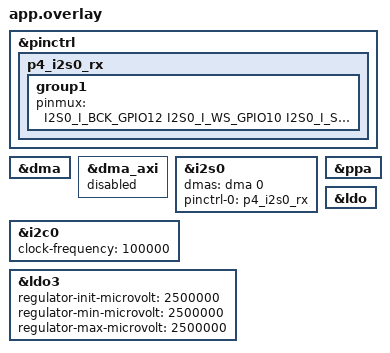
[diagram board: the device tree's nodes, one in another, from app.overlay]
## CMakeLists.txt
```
# SPDX-License-Identifier: MPL-2.0
cmake_minimum_required(VERSION 3.28)
find_package(Zephyr REQUIRED HINTS $ENV{ZEPHYR_BASE})
project(p4_microblocks LANGUAGES C CXX)
get_filename_component(repo "${CMAKE_CURRENT_SOURCE_DIR}/../../.." ABSOLUTE)
execute_process(COMMAND ${Python3_EXECUTABLE} "${repo}/tools/apply_p4_zephyr_patches.py"
  --zephyr "${ZEPHYR_BASE}" --require-applied COMMAND_ERROR_IS_FATAL ANY)
if(NOT SMALLVM_SOURCE_DIR)
  set(SMALLVM_SOURCE_DIR "${repo}/build-artifacts/p4-sources/smallvm")
endif()
set(vm_root "${CMAKE_CURRENT_BINARY_DIR}/smallvm")
execute_process(COMMAND ${Python3_EXECUTABLE} "${repo}/tools/prepare_p4_zephyr_runtime.py"
  "${SMALLVM_SOURCE_DIR}" "${vm_root}" COMMAND_ERROR_IS_FATAL ANY)
target_include_directories(app PRIVATE "${vm_root}" "${vm_root}/vm" "${repo}/common/image" "${repo}/common/audio" "${repo}/common/media" src "${ZEPHYR_BASE}/drivers/video")
target_include_directories(app PRIVATE "${repo}/common/nn" "${repo}/common/i2c")
target_compile_definitions(app PRIVATE SMALLVM_ZEPHYR=1 HAS_BOARD_HOOKS=1 IMAGE_ALLOC_EXTERNAL=1 AUDIO_ALLOC_EXTERNAL=1 MEDIA_ALLOC_EXTERNAL=1)
if(CONFIG_ESP_HOSTED_MCU)
  target_include_directories(app PRIVATE "${ZEPHYR_BASE}/drivers/misc/esp_hosted_mcu")
endif()
target_sources(app PRIVATE src/main.c src/platform.c src/image_primitives.c src/camera_backend.c
  src/p4_sensors.c src/p4_csi.c src/audio_backend.c src/whistle_backend.c src/media_protocol.c src/c6_trace.c
  "${repo}/common/image/image_store.c"
  "${repo}/common/audio/audio_store.c"
  "${repo}/common/media/result_store.c"
  ${vm_root}/vm/interp.c ${vm_root}/vm/runtime.c ${vm_root}/vm/mem.c
  ${vm_root}/vm/persist.c ${vm_root}/vm/dataPrims.c ${vm_root}/vm/varPrims.c
  ${vm_root}/vm/tinyJSON.c ${vm_root}/vm/mbFont.c ${vm_root}/vm/boardHooks.c)
target_sources(app PRIVATE src/neural_primitives.c "${repo}/common/nn/nn_contract.c")
target_sources(app PRIVATE src/discovery_backend.c src/discovery_primitives.c "${repo}/common/i2c/discovery.c")
target_sources(app PRIVATE src/ppa_backend.c)

# Actual RoboEyes with a native framebuffer facade; no ArduinoCore dependency.
if(NOT ROBOEYES_SOURCE_DIR)
  set(ROBOEYES_SOURCE_DIR "${repo}/build-artifacts/roboeyes")
endif()
execute_process(COMMAND ${Python3_EXECUTABLE} "${repo}/tools/fetch_roboeyes.py"
  --output "${ROBOEYES_SOURCE_DIR}" --verify COMMAND_ERROR_IS_FATAL ANY)
target_include_directories(app PRIVATE "${repo}/common/eyes" "${repo}/common/pose" "${ROBOEYES_SOURCE_DIR}/src")
target_sources(app PRIVATE src/eyes_backend.c src/eyes_primitives.c
  "${repo}/common/eyes/oled.c" "${repo}/common/eyes/roboeyes.cpp" "${repo}/common/pose/pose.c"
  src/pose_camera.c src/camera_tuning.c src/serial_speed.c "${repo}/common/pose/camera_wire.c" "${repo}/common/pose/face.c" "${repo}/common/pose/serial_rate.c")

# Portable JSON service; append its primitive set without changing p4:* indices.
target_include_directories(app PRIVATE "${repo}/common/json" "${repo}/third_party/yyjson")
target_sources(app PRIVATE "${repo}/common/json/json_service.c" "${repo}/common/json/json_primitives.c" "${repo}/third_party/yyjson/yyjson.c")
set_source_files_properties("${repo}/third_party/yyjson/yyjson.c" PROPERTIES COMPILE_OPTIONS "-include;${repo}/common/json/json_config.h")

target_include_directories(app PRIVATE "${repo}/common/automation")
target_sources(app PRIVATE "${repo}/common/automation/clock.c" "${repo}/common/automation/steps.c" "${repo}/common/automation/primitives.c")
target_include_directories(app PRIVATE "${repo}/common/storage")
target_sources(app PRIVATE "${repo}/common/storage/storage.c" "${repo}/common/storage/storage_primitives.c"
  "${repo}/common/storage/dispatcher.c" "${repo}/common/storage/wire.c"
  "${repo}/common/storage/controller.c" "${repo}/common/storage/storage_protocol.c")
target_sources(app PRIVATE src/kws_primitives.c src/voice_primitives.c)
if(P4_VOICE_MODEL)
  if(NOT P4_KWS_MODEL)
    message(FATAL_ERROR "Voice commands share the KWS worker; also supply the pinned P4_KWS_MODEL")
  endif()
  set(voice_generated "${CMAKE_CURRENT_BINARY_DIR}/voice")
  get_filename_component(voice_model_dir "${P4_VOICE_MODEL}" DIRECTORY)
  get_filename_component(voice_model_stem "${P4_VOICE_MODEL}" NAME_WE)
  set_property(DIRECTORY APPEND PROPERTY CMAKE_CONFIGURE_DEPENDS "${repo}/bilingual-kws/scripts/prepare_firmware.py" "${P4_VOICE_MODEL}" "${voice_model_dir}/${voice_model_stem}.json")
  execute_process(COMMAND ${Python3_EXECUTABLE} "${repo}/bilingual-kws/scripts/prepare_firmware.py"
    --model "${P4_VOICE_MODEL}" --output "${voice_generated}" COMMAND_ERROR_IS_FATAL ANY)
  target_compile_definitions(app PRIVATE P4_VOICE_COMMANDS=1)
  target_include_directories(app PRIVATE "${voice_generated}" "${repo}/bilingual-kws/esp32p4/integration")
  target_sources(app PRIVATE "${voice_generated}/voice_assets.S" "${repo}/bilingual-kws/esp32p4/integration/decision.c")
endif()
if(P4_KWS_MODEL)
  if(NOT CONFIG_P4_NEURAL OR NOT P4_TFLM_SOURCE)
    message(FATAL_ERROR "KWS requires the pinned TFLM neural profile")
  endif()
  set(kws_generated "${CMAKE_CURRENT_BINARY_DIR}/kws")
  set(kws_args --tflm "${P4_TFLM_SOURCE}" --model "${P4_KWS_MODEL}" --output "${kws_generated}")
  if(P4_KWS_POSITIVE AND P4_KWS_NEGATIVE)
    list(APPEND kws_args --positive "${P4_KWS_POSITIVE}" --negative "${P4_KWS_NEGATIVE}")
  endif()
  set_property(DIRECTORY APPEND PROPERTY CMAKE_CONFIGURE_DEPENDS "${repo}/tools/prepare_p4_kws.py" "${repo}/tools/prepare_p4_kws_frontend.py" "${P4_KWS_MODEL}")
  execute_process(COMMAND ${Python3_EXECUTABLE} "${repo}/tools/prepare_p4_kws.py" ${kws_args} COMMAND_ERROR_IS_FATAL ANY)
  set(kws_frontend "${P4_TFLM_SOURCE}/tensorflow/lite/experimental/microfrontend/lib")
  set(kws_external "${kws_generated}/filterbank_util_checked.c")
  foreach(source filterbank frontend frontend_util log_lut log_scale log_scale_util noise_reduction noise_reduction_util pcan_gain_control pcan_gain_control_util window window_util)
    list(APPEND kws_external "${kws_frontend}/${source}.c")
  endforeach()
  foreach(source fft fft_util kiss_fft_int16)
    list(APPEND kws_external "${kws_frontend}/${source}.cc")
  endforeach()
  # Redirect only frontend allocations; never alter the TFLM/custom NN allocator.
  set_source_files_properties(${kws_external} PROPERTIES COMPILE_OPTIONS "-include;${repo}/common/kws/alloc_redirect.h")
  target_include_directories(app PRIVATE "${repo}/common/kws" "${kws_generated}" "${P4_TFLM_SOURCE}/third_party_static/kissfft")
  target_sources(app PRIVATE src/kws_backend.cpp "${repo}/common/kws/features.c" "${kws_generated}/kws_assets.S" ${kws_external})
else()
  target_sources(app PRIVATE src/kws_stub.c)
endif()
if(CONFIG_P4_NEURAL)
  if(NOT P4_TFLM_SOURCE)
    message(FATAL_ERROR "Pass P4_TFLM_SOURCE for the pinned TFLM module and ZEPHYR_EXTRA_MODULES")
  endif()
  set(nn_generated "${CMAKE_CURRENT_BINARY_DIR}/neural")
  set_property(DIRECTORY APPEND PROPERTY CMAKE_CONFIGURE_DEPENDS "${repo}/tools/prepare_p4_neural.py")
  execute_process(COMMAND ${Python3_EXECUTABLE} "${repo}/tools/prepare_p4_neural.py"
    --source "${ZEPHYR_BASE}/samples/modules/tflite-micro/hello_world/src/model.cpp"
    --tflm "${P4_TFLM_SOURCE}" --output "${nn_generated}" COMMAND_ERROR_IS_FATAL ANY)
  # Error strings must never corrupt the binary SmallVM transport on UART0.
  zephyr_compile_definitions(TF_LITE_STRIP_ERROR_STRINGS)
  target_include_directories(app PRIVATE "${nn_generated}")
  target_sources(app PRIVATE src/neural_backend.cpp "${nn_generated}/neural_builtin.S")
else()
  target_sources(app PRIVATE src/neural_stub.c)
endif()
# Native HAL only: no esp_driver_cam/ISP FreeRTOS drivers are linked.
if(CONFIG_P4_HOSTED)
  if(NOT TARGET modules__nanopb OR NOT CONFIG_ESP_SPIRAM)
    message(FATAL_ERROR "Hosted RPC isolation requires pinned nanopb and initialized PSRAM")
  endif()
  target_compile_options(modules__nanopb PRIVATE "SHELL:-include ${CMAKE_CURRENT_SOURCE_DIR}/src/rpc_allocator.h")
  target_sources(app PRIVATE src/rpc_allocator.c src/rpc_decode.c)
  add_custom_target(p4_rpc_memory_validate ALL DEPENDS zephyr_final
    COMMAND ${Python3_EXECUTABLE} "${repo}/tools/check_p4_rpc_memory.py"
      --elf "${CMAKE_BINARY_DIR}/zephyr/zephyr.elf" --objdump "${CMAKE_OBJDUMP}")
  if(NOT CONFIG_COMMON_LIBC_MALLOC OR NOT CONFIG_COMMON_LIBC_MALLOC_ARENA_SIZE EQUAL -1)
    message(FATAL_ERROR "Hosted memory guard requires the audited automatic libc arena")
  endif()
  if(CONFIG_HTTP_SERVER_VERSION_2 OR CONFIG_NET_SOCKETS_OFFLOAD)
    message(FATAL_ERROR "Re-audit asset buffer ownership before enabling HTTP/2 or socket offload")
  endif()
  zephyr_linker_section(NAME http_resource_desc_p4_http KVMA RAM_REGION GROUP RODATA_REGION)
  zephyr_linker_sources(SECTIONS sections-rom.ld)
  if(NOT P4_HOSTED_ASSETS_DIR)
    set(P4_HOSTED_ASSETS_DIR "${repo}/build-artifacts/p4-hosted-assets")
  endif()
  if(NOT EXISTS "${P4_HOSTED_ASSETS_DIR}/assets.c")
    message(FATAL_ERROR "Run tools/package_p4_hosted.py before building hosted profile")
  endif()
  target_sources(app PRIVATE src/hosted_transport.c src/hosted_server.c src/network_backend.c "${P4_HOSTED_ASSETS_DIR}/assets.c")
  set(hosted_layout_args --elf "${CMAKE_BINARY_DIR}/zephyr/zephyr.elf" --image "${CMAKE_BINARY_DIR}/zephyr/zephyr.bin" --assets "${P4_HOSTED_ASSETS_DIR}/assets.bin" --dts "${CMAKE_BINARY_DIR}/zephyr/zephyr.dts")
  if(NOT P4_WHISTLE_MODEL)
    list(APPEND hosted_layout_args --allow-no-model)
  endif()
  add_custom_target(p4_hosted_layout ALL DEPENDS zephyr_final
    COMMAND ${Python3_EXECUTABLE} "${repo}/tools/check_p4_hosted_layout.py" ${hosted_layout_args})
endif()
target_sources(app PRIVATE
  ${ZEPHYR_HAL_ESPRESSIF_MODULE_DIR}/components/esp_hal_cam/mipi_csi_hal.c
  ${ZEPHYR_HAL_ESPRESSIF_MODULE_DIR}/components/esp_hal_cam/esp32p4/mipi_csi_periph.c
  ${ZEPHYR_HAL_ESPRESSIF_MODULE_DIR}/components/esp_hal_dma/dw_gdma_hal.c)

if(P4_WHISTLE_MODEL)
  if(NOT P4_WHISTLE_SOURCES)
    set(P4_WHISTLE_SOURCES "${repo}/build-artifacts/whistle-sources")
  endif()
  set(whistle_generated "${CMAKE_CURRENT_BINARY_DIR}/whistle")
  set(whistle_args --sources "${P4_WHISTLE_SOURCES}" --model "${P4_WHISTLE_MODEL}" --output "${whistle_generated}")
  if(P4_WHISTLE_FIXTURE)
    list(APPEND whistle_args --fixture "${P4_WHISTLE_FIXTURE}")
    target_compile_definitions(app PRIVATE P4_WHISTLE_FIXTURE=1)
  endif()
  execute_process(COMMAND ${Python3_EXECUTABLE} "${repo}/tools/prepare_p4_whistle.py" ${whistle_args}
    COMMAND_ERROR_IS_FATAL ANY)
  target_compile_definitions(app PRIVATE P4_WHISTLE=1)
  target_include_directories(app PRIVATE "${P4_WHISTLE_SOURCES}/engine/include")
  target_sources(app PRIVATE "${whistle_generated}/whistle_assets.S")
  foreach(source nd_cact nd_quant nd_tokenizer nd_ledcmd nd_whistle)
    target_sources(app PRIVATE "${whistle_generated}/${source}_zephyr.c")
  endforeach()
  add_custom_target(p4_whistle_validate ALL DEPENDS zephyr_final
    COMMAND ${Python3_EXECUTABLE} "${repo}/tools/check_p4_whistle_image.py"
      --elf "${CMAKE_BINARY_DIR}/zephyr/zephyr.elf"
      --bin "${CMAKE_BINARY_DIR}/zephyr/zephyr.bin")
endif()
```

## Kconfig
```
# SPDX-License-Identifier: MPL-2.0
mainmenu "Native P4 MicroBlocks"
source "Kconfig.zephyr"
config P4_HOSTED
 bool "P4-hosted editor on the approved station network"
 depends on WIFI_ESP_HOSTED_MCU_DEFER_STATION
 default n
config P4_NEURAL
 bool "Bounded native TFLM dense model backend"
 depends on TENSORFLOW_LITE_MICRO && CPP
 default n
config P4_IMX219_EXPOSURE_LINES
 int "IMX219 manual exposure in lines (no AE)"
 range 4 1156
 default 800
config P4_IMX219_ANALOG_GAIN
 int "IMX219 analogue gain register (0=1x, 232=10.67x)"
 range 0 232
 default 128
config P4_IMX219_DIGITAL_GAIN
 int "IMX219 digital gain register (256=1x)"
 range 256 4095
 default 256
config P4_IMX219_TEST_PATTERN
 int "IMX219 diagnostic test pattern; 0 is real imaging, 2 is colour bars"
 range 0 4
 default 0
```

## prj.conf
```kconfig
CONFIG_CONSOLE=n
CONFIG_UART_CONSOLE=n
CONFIG_SERIAL=y
CONFIG_UART_INTERRUPT_DRIVEN=y
CONFIG_UART_USE_RUNTIME_CONFIGURE=y
CONFIG_LOG=n
CONFIG_MAIN_STACK_SIZE=16384
CONFIG_HEAP_MEM_POOL_SIZE=16384
CONFIG_PICOLIBC=y
CONFIG_PICOLIBC_IO_FLOAT=y
CONFIG_CBPRINTF_FP_SUPPORT=y
CONFIG_ESP_SPIRAM=y
CONFIG_ESP_SPIRAM_HEAP_SIZE=16777216
CONFIG_ESP_SPIRAM_MEMTEST=y
CONFIG_I2C=y
CONFIG_CPP=y
CONFIG_STD_CPP17=y
CONFIG_RING_BUFFER=y
CONFIG_GPIO=y
CONFIG_ASSERT=y
CONFIG_VIDEO=y
CONFIG_VIDEO_DRIVERS=y
CONFIG_VIDEO_BUFFER_POOL_HEAP_SIZE=0
CONFIG_REGULATOR=y
CONFIG_CACHE_MANAGEMENT=y
CONFIG_I2S=y
CONFIG_I2S_ESP32_RX_BLOCK_COUNT=4
CONFIG_ESP32_PPA=y
CONFIG_ESP32_PPA_WAIT_TIMEOUT_US=100000
CONFIG_ESP32_PPA_MAX_PENDING=1
```

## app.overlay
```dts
/* SPDX-License-Identifier: Apache-2.0 */
#include <zephyr/dt-bindings/pinctrl/esp32p4-pinctrl.h>
&pinctrl {
    p4_i2s0_rx: p4_i2s0_rx {
        group1 {
            pinmux = <I2S0_I_BCK_GPIO12 I2S0_I_WS_GPIO10 I2S0_I_SD_GPIO11 I2S0_MCLK_GPIO13>;
        };
    };
};
/* P4's I2S0 trigger is on AHB GDMA (hal/gdma_channel.h), independently
 * of the camera's dedicated DW-GDMA. AXI cannot service this peripheral. */
&dma { status = "okay"; };
/* The board default enables AXI GDMA too, allocating six unused CPU
 * interrupt vectors. Camera uses DW-GDMA and audio uses AHB, so leave
 * AXI off to retain vectors for SDIO and future required peripherals. */
&dma_axi { status = "disabled"; };
&i2s0 {
    status = "okay";
    dmas = <&dma 0>;
    dma-names = "rx";
    pinctrl-0 = <&p4_i2s0_rx>;
    pinctrl-names = "default";
};
&i2c0 { clock-frequency = <100000>; };
&ppa { status = "okay"; };
/* Dedicated MIPI D-PHY supply, matching the board and tested camera source.
 * Other LDOs (including PSRAM) retain their board settings. */
&ldo { status = "okay"; };
&ldo3 {
    regulator-init-microvolt = <2500000>;
    regulator-min-microvolt = <2500000>;
    regulator-max-microvolt = <2500000>;
};
```

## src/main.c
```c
/* SPDX-License-Identifier: MPL-2.0 */
#include <zephyr/kernel.h>
#include "vm/interp.h"
#include "vm/persist.h"
#include "media_protocol.h"
#include "neural_backend.h"
#include "kws_primitives.h"
#include "primitives.h"
#include "storage_primitives.h"
#include "storage_protocol.h"
#include "eyes_backend.h"
#include "pose_camera.h"
#include "camera_tuning.h"
#include "serial_speed.h"
#if defined(CONFIG_P4_HOSTED)
#include "hosted_server.h"
#endif
int main(void) {
    hardwareInit();memInit();primsInit();restoreScripts();startAll();
    for(;;){
#if defined(CONFIG_P4_HOSTED)
        p4_transport_poll();
#endif
        vmSlice(32);p4_serial_speed_poll();p4_media_poll();p4_nn_poll();p4_kws_poll();mb_automation_poll();mb_storage_poll();
        mb_storage_protocol_poll(k_uptime_get(),ideConnected());p4_pose_camera_poll();p4_camera_tuning_poll();p4_eyes_poll();k_sleep(K_MSEC(1));}
}
```

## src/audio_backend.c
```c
/* SPDX-FileCopyrightText: 2023 Espressif Systems (Shanghai) CO LTD
 * SPDX-License-Identifier: Apache-2.0
 * ES8311 register setup adapted from esp_codec_dev 1.5.4 es8311.c.
 * Zephyr transport/worker/lifetime integration: microblocks-zephyr authors.
 * ADC-only, analog microphone, 16 kHz/16 bit, MCLK=256*Fs. No speaker/TX.
 */
#include <zephyr/kernel.h>
#include <zephyr/drivers/i2c.h>
#include <zephyr/drivers/i2s.h>
#include <zephyr/drivers/gpio.h>
#include <zephyr/multi_heap/shared_multi_heap.h>
#include <zephyr/sys/atomic.h>
#include <errno.h>
#include <stdio.h>
#include <string.h>
#include "audio_backend.h"
#include "audio_store.h"
#include "discovery_backend.h"
#ifdef P4_AUDIO_DIAGNOSTIC
#include <zephyr/drivers/uart.h>
#include <zephyr/fatal.h>
static void trace(const char *s){const struct device *d=DEVICE_DT_GET(DT_NODELABEL(uart0));while(*s)uart_poll_out(d,*s++);uart_poll_out(d,'\n');}
void k_sys_fatal_error_handler(unsigned int reason,const struct arch_esf *esf){
    char s[128];snprintf(s,sizeof(s),"audio: fatal reason=%u pc=%lx ra=%lx",reason,esf?esf->mepc:0ul,esf?esf->ra:0ul);trace(s);
    for(;;)arch_cpu_idle();
}
#else
#define trace(s) do{}while(0)
#endif
static const struct device *const bus=DEVICE_DT_GET(DT_NODELABEL(i2c0));
static const struct device *const rx=DEVICE_DT_GET(DT_NODELABEL(i2s0));
static const struct device *const amp_gpio=DEVICE_DT_GET(DT_NODELABEL(gpio1));
#define CODEC 0x18
#define BLOCK 1024u
#define SLABS 6u
K_MEM_SLAB_DEFINE_STATIC(dma_slab,BLOCK,SLABS,64);
K_SEM_DEFINE(audio_requested,0,1);
K_MUTEX_DEFINE(audio_mutex);
static atomic_t cancelled;
enum { IDLE,RECORDING,STREAMING,READY,ERROR,FAULT };
static int state,identity;
static unsigned requested_frames;
static int16_t *pending;
static p4_audio_sink stream_sink;
static void *stream_context;
static char message[192]="idle; microphone is off";
void *audio_alloc(size_t n){return shared_multi_heap_aligned_alloc(SMH_REG_ATTR_EXTERNAL,64,n);}
void audio_free(void *p){if(p)shared_multi_heap_free(p);}
static int wr(uint8_t r,uint8_t v){return i2c_reg_write_byte(bus,CODEC,r,v);}
static int probe(void)
{
    uint8_t a,b;
    if(!device_is_ready(bus) || i2c_reg_read_byte(bus,CODEC,0xfd,&a) ||
       i2c_reg_read_byte(bus,CODEC,0xfe,&b))return 0;
    return ((unsigned)a<<8)|b;
}
int p4_audio_codec_id(void)
{
    k_mutex_lock(&audio_mutex,K_FOREVER);
    if(state!=RECORDING && state!=STREAMING)identity=probe();
    int result=identity;k_mutex_unlock(&audio_mutex);return result;
}
int p4_audio_available(void){return identity==0x8311 && device_is_ready(rx);}
static int codec_stop(void)
{
    /* Disable serial ADC output before powering down. Keep DAC and PA off. */
    static const uint8_t stop[][2]={{0x0a,0x4c},{0x09,0x4c},{0x31,0x60},{0x17,0},
        {0x0e,0xff},{0x12,2},{0x14,0},{0x0d,0xfa},{0x15,0},{0x02,0x10},
        {0x00,0},{0x00,0x1f},{0x01,0x30},{0x01,0},{0x45,0}};
    int error=0;
    for(unsigned i=0;i<ARRAY_SIZE(stop);i++){int e=wr(stop[i][0],stop[i][1]);if(e && !error)error=e;}
    return error;
}
void p4_audio_init(void)
{
    if(device_is_ready(amp_gpio))gpio_pin_configure(amp_gpio,21,GPIO_OUTPUT_INACTIVE);
    identity=probe();
    if(identity==0x8311){int error=codec_stop();
        snprintf(message,sizeof(message),error?"ES8311 detected; stop error %d":"ES8311 detected; microphone off",error);}
}
static int codec_start(void)
{
    /* Vendor 4.096 MHz/16 kHz clock table: prediv1, ADC/DAC div1,
     * single-speed, LRCK divider256, BCLK div4, ADC OSR0x10. */
    static const uint8_t start[][2]={{0x44,8},{0x44,8},{0x01,0x30},{0x02,0},
        {0x03,0x10},{0x16,4},{0x04,0x20},{0x05,0},{0x0b,0},{0x0c,0},
        {0x10,0x1f},{0x11,0x7f},{0x00,0x80},{0x01,0x3f},{0x06,3},
        {0x07,0},{0x08,0xff},{0x09,0x4c},{0x0a,0x4c},
        {0x13,0x10},{0x1b,0x0a},{0x1c,0x6a},{0x44,8},
        {0x17,0xbf},{0x0e,2},{0x12,2},{0x14,0x1a},{0x0d,1},
        {0x15,0x40},{0x37,8},{0x45,0},{0x0a,0x0c}};
    for(unsigned i=0;i<ARRAY_SIZE(start);i++){int e=wr(start[i][0],start[i][1]);if(e)return e;}
    return 0;
}
static int capture(int16_t *pcm,unsigned frames,bool stream,char *detail,size_t size)
{
    trace("audio: amp");
    if(!device_is_ready(amp_gpio))return -ENODEV;
    int error=gpio_pin_configure(amp_gpio,21,GPIO_OUTPUT_INACTIVE);
    if(error)return error;
    trace("audio: probe");if(probe()!=0x8311)return -ENODEV;
    struct i2s_config cfg={.word_size=16,.channels=2,.format=I2S_FMT_DATA_FORMAT_I2S,
        .options=I2S_OPT_BIT_CLK_MASTER|I2S_OPT_FRAME_CLK_MASTER,
        .frame_clk_freq=AUDIO_RATE,.mem_slab=&dma_slab,.block_size=BLOCK,.timeout=100};
    trace("audio: configure");error=i2s_configure(rx,I2S_DIR_RX,&cfg);
    if(error){snprintf(detail,size,"configure %d",error);return error;}
    trace("audio: codec start");error=codec_start();
    uint64_t started_us=k_cyc_to_us_floor64(k_cycle_get_64());
    trace("audio: trigger");if(!error)error=i2s_trigger(rx,I2S_DIR_RX,I2S_TRIGGER_START);
    trace("audio: reading");
    uint64_t copied=0;
    unsigned skip=2,blocks=0;
    uint64_t left_energy=0,right_energy=0;
    int64_t deadline=k_uptime_get()+(uint64_t)frames*1000/AUDIO_RATE+1500;
    while(!error && ((stream && !frames) || copied<frames)){
        if(atomic_get(&cancelled)){error=-ECANCELED;break;}
        if(frames && k_uptime_get()>deadline){error=-ETIMEDOUT;break;}
        void *data=NULL;size_t bytes=0;
        error=i2s_read(rx,&data,&bytes);
        if(error)break;
        if(!data || bytes!=BLOCK){if(data)k_mem_slab_free(&dma_slab,data);error=-EIO;break;}
        int16_t *s=data;blocks++;
        if(skip)skip--;
        else {
            int16_t mono[BLOCK/4];unsigned count=0;
            for(unsigned i=0;i<bytes/4 && (!frames || copied<frames);i++){
                int32_t l=s[2*i],r=s[2*i+1];
                /* Long listeners do not accumulate unbounded energy sums. */
                if(!stream){left_energy+=(int64_t)l*l;right_energy+=(int64_t)r*r;pcm[copied]=(int16_t)l;}
                else mono[count++]=(int16_t)l;
                copied++;
            }
            if(stream && count && !stream_sink(mono,count,stream_context))error=atomic_get(&cancelled)?-ECANCELED:-ENOBUFS;
            if(stream)memset(mono,0,sizeof(mono));
        }
        k_mem_slab_free(&dma_slab,data);
    }
    uint64_t dma_us=k_cyc_to_us_floor64(k_cycle_get_64())-started_us;
    trace("audio: stop");int off=codec_stop();
    int dropped=i2s_trigger(rx,I2S_DIR_RX,I2S_TRIGGER_DROP);
    unsigned inuse=k_mem_slab_num_used_get(&dma_slab);
    if(stream)snprintf(detail,size,"%llu/%u frames, %u blocks, %llu us, energy not accumulated, drop=%d slab=%u off=%d",
        (unsigned long long)copied,frames,blocks,(unsigned long long)dma_us,dropped,inuse,off);
    else snprintf(detail,size,"%llu/%u frames, %u blocks, %llu us, L=%llu R=%llu, drop=%d slab=%u off=%d",
        (unsigned long long)copied,frames,blocks,(unsigned long long)dma_us,(unsigned long long)left_energy,(unsigned long long)right_energy,dropped,inuse,off);
    /* A failed DROP never permits reuse of the permanently allocated DMA slab.
     * PCM is CPU-only, so it can be erased/released independently. */
    if(dropped || inuse || off)return -EBUSY;
    if(!error)error=off;
    return error;
}
static void worker(void *a,void *b,void *c)
{
    ARG_UNUSED(a);ARG_UNUSED(b);ARG_UNUSED(c);
    for(;;){
        k_sem_take(&audio_requested,K_FOREVER);
        bool stream=state==STREAMING;
        unsigned frames=requested_frames;
        int16_t *pcm=stream?NULL:audio_alloc(frames*sizeof(int16_t));
        char detail[144]="allocation failed";
        int error=(stream||pcm)?capture(pcm,frames,stream,detail,sizeof(detail)):-ENOMEM;
        k_mutex_lock(&audio_mutex,K_FOREVER);
        if(error || atomic_get(&cancelled)){
            if(pcm){memset(pcm,0,frames*sizeof(int16_t));audio_free(pcm);}
            state=error==-EBUSY?FAULT:atomic_get(&cancelled)?IDLE:ERROR;
            snprintf(message,sizeof(message),"record error %d; %s",error,detail);
        }else if(stream){state=IDLE;snprintf(message,sizeof(message),"Stream stopped; %s",detail);}
        else{pending=pcm;state=READY;snprintf(message,sizeof(message),"PCM ready; mic stopped; %s",detail);}
        if(stream){stream_sink=NULL;stream_context=NULL;}
        k_mutex_unlock(&audio_mutex);
    }
}
K_THREAD_DEFINE(audio_thread,8192,worker,NULL,NULL,NULL,7,0,0);
int p4_audio_request(unsigned ms)
{
    if(p4_discovery_busy())return 0;
    k_mutex_lock(&audio_mutex,K_FOREVER);
    if(state==RECORDING || state==STREAMING || state==READY || state==FAULT || ms<20 || ms>8000 ||
       audio_count()>=AUDIO_SLOTS || !device_is_ready(rx)){
        k_mutex_unlock(&audio_mutex);return 0;
    }
    identity=probe();
    if(identity!=0x8311){snprintf(message,sizeof(message),"ES8311 identity unavailable: %04x",identity);k_mutex_unlock(&audio_mutex);return 0;}
    requested_frames=ms*(AUDIO_RATE/1000);atomic_clear(&cancelled);state=RECORDING;
    snprintf(message,sizeof(message),"recording bounded %u ms",ms);
    k_sem_give(&audio_requested);k_mutex_unlock(&audio_mutex);return 1;
}
int p4_audio_busy(void){k_mutex_lock(&audio_mutex,K_FOREVER);int b=state==RECORDING||state==STREAMING;k_mutex_unlock(&audio_mutex);return b;}
int p4_audio_stream_start(unsigned ms,p4_audio_sink sink,void *context)
{
    if(!sink||ms>300000||p4_discovery_busy())return 0;
    k_mutex_lock(&audio_mutex,K_FOREVER);
    int ok=state!=RECORDING&&state!=STREAMING&&state!=READY&&state!=FAULT&&device_is_ready(rx);
    if(ok){identity=probe();ok=identity==0x8311;}
    if(ok){requested_frames=ms*(AUDIO_RATE/1000);stream_sink=sink;stream_context=context;state=STREAMING;atomic_clear(&cancelled);snprintf(message,sizeof(message),"Explicit wake-word stream starting");k_sem_give(&audio_requested);}
    k_mutex_unlock(&audio_mutex);return ok;
}
void p4_audio_stream_stop(void){k_mutex_lock(&audio_mutex,K_FOREVER);if(state==STREAMING)atomic_set(&cancelled,1);k_mutex_unlock(&audio_mutex);}
int p4_audio_stream_state(void){k_mutex_lock(&audio_mutex,K_FOREVER);int value=state==STREAMING?1:(state==ERROR||state==FAULT)?-1:0;k_mutex_unlock(&audio_mutex);return value;}
int p4_audio_result(void)
{
    k_mutex_lock(&audio_mutex,K_FOREVER);int h=0;
    if(state==READY){h=audio_adopt(pending,requested_frames);
        if(!h){memset(pending,0,requested_frames*2);audio_free(pending);}
        pending=NULL;state=IDLE;}
    else if(state==ERROR)state=IDLE;
    k_mutex_unlock(&audio_mutex);return h;
}
void p4_audio_discard(void)
{
    k_mutex_lock(&audio_mutex,K_FOREVER);atomic_set(&cancelled,1);
    if(state==READY){memset(pending,0,requested_frames*2);audio_free(pending);pending=NULL;state=IDLE;}
    if(state==ERROR)state=IDLE;
    k_mutex_unlock(&audio_mutex);
}
const char *p4_audio_status(void)
{
    static char snapshot[sizeof(message)];k_mutex_lock(&audio_mutex,K_FOREVER);
    memcpy(snapshot,message,sizeof(message));k_mutex_unlock(&audio_mutex);return snapshot;
}
```

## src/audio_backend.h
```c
/* SPDX-License-Identifier: MIT */
#pragma once
#include <stdint.h>
void p4_audio_init(void);
int p4_audio_codec_id(void);
int p4_audio_available(void);
int p4_audio_request(unsigned milliseconds);
int p4_audio_busy(void);
int p4_audio_result(void);
void p4_audio_discard(void);
const char *p4_audio_status(void);
/* Called on the audio worker with a temporary mono block. Copy immediately;
 * never retain its pointer or block this callback on inference/VM work. */
typedef int (*p4_audio_sink)(const int16_t *,unsigned,void *);
int p4_audio_stream_start(unsigned milliseconds,p4_audio_sink sink,void *context);
void p4_audio_stream_stop(void);
int p4_audio_stream_state(void); /* 1 running, 0 stopped, -1 error/quarantined */
```

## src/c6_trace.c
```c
/* SPDX-License-Identifier: MPL-2.0 */
#include "c6_trace.h"
#include <stdio.h>
#include <stdint.h>
#if defined(CONFIG_ESP_HOSTED_MCU)
#include <zephyr/kernel.h>
#include <string.h>
#include <pb_decode.h>
#include "esp_hosted_mcu.h"
typedef struct {uint32_t interface,number,flags,packet_type,length,offset,sequence;} trace_header;
typedef struct {
 uint32_t rx_polls,rx_counter,rx_consumed,tx_credit_polls,tx_credits,tx_spent;
 uint32_t rx_transfers,rx_bytes,tx_transfers,tx_bytes,invalid_headers,valid_headers;
 uint32_t bus_errors,floating_reads,interrupt_status;
 int last_bus_error,version_rpc_error;
 uint32_t tlv_length,endpoint_length,endpoint_kind,rpc_type,rpc_id,rpc_uid,rpc_payload,rpc_decode_errors,tag_count,tags[8][3];
 uint32_t request_id,request_payload,request_uid,request_checksum;
 trace_header first[8];
} trace_state;
static trace_state state;
static struct k_spinlock trace_lock;
static struct {bool busy;unsigned count;int result,reply_id,reply_status;int64_t elapsed;} control;
K_SEM_DEFINE(control_ready,0,1);
#if !defined(CONFIG_P4_HOSTED)
static void control_worker(void *a,void *b,void *c)
{
 (void)a;(void)b;(void)c;
 for(;;){
  k_sem_take(&control_ready,K_FOREVER);
  Rpc req=Rpc_init_zero,resp=Rpc_init_zero;
  req.msg_id=RpcId_Req_GetMACAddress;req.which_payload=Rpc_req_get_mac_address_tag;
  req.payload.req_get_mac_address.mode=0;
  int64_t began=k_uptime_get();int result=esp_hosted_mcu_rpc_call(&req,&resp,5000);
  int reply=resp.msg_id,status=resp.which_payload==Rpc_resp_get_mac_address_tag?resp.payload.resp_get_mac_address.resp:-1;
  /* The returned address is never copied to diagnostic storage or output. */
  pb_release(Rpc_fields,&resp);memset(&req,0,sizeof(req));memset(&resp,0,sizeof(resp));
  k_spinlock_key_t key=k_spin_lock(&trace_lock);
  control.result=result;control.reply_id=reply;control.reply_status=status;control.elapsed=k_uptime_get()-began;control.busy=false;
  k_spin_unlock(&trace_lock,key);
 }
}
K_THREAD_DEFINE(c6_control_worker,16384,control_worker,NULL,NULL,NULL,8,0,0);
int p4_c6_query_start(void)
{
 k_spinlock_key_t key=k_spin_lock(&trace_lock);
 if(control.busy){k_spin_unlock(&trace_lock,key);return 0;}
 control.busy=true;control.count++;control.result=-EINPROGRESS;control.reply_id=0;control.reply_status=-1;
 k_spin_unlock(&trace_lock,key);k_sem_give(&control_ready);return 1;
}
#else
/* Production AP control owns RPCs; the optional diagnostic needs no stack. */
int p4_c6_query_start(void){return 0;}
#endif
unsigned p4_c6_query_count(void){k_spinlock_key_t key=k_spin_lock(&trace_lock);unsigned n=control.count;k_spin_unlock(&trace_lock,key);return n;}
static void increment(uint32_t *value){if(*value!=UINT32_MAX)(*value)++;}
/* Called only with metadata: no payload address can enter this recorder. */
void esp_hosted_mcu_diag(unsigned stage,uint32_t a,uint32_t b,uint32_t c,uint32_t d,int error)
{
 (void)c;
 k_spinlock_key_t key=k_spin_lock(&trace_lock);
 if(stage==1){
  if(state.valid_headers<8)state.first[state.valid_headers]=(trace_header){a&15,(a>>8)&15,(a>>16)&255,a>>24,b,c,d};
  increment(&state.valid_headers);
 }else if(stage==2)increment(&state.invalid_headers);
 else if(stage==3){increment(&state.rx_polls);state.rx_counter=a;state.rx_consumed=b;if(a==0xfffff)increment(&state.floating_reads);}
 else if(stage==4){increment(&state.tx_credit_polls);state.tx_credits=a;state.tx_spent=b;}
 else if(stage==5){
  if(a){increment(&state.tx_transfers);if(!error && UINT32_MAX-state.tx_bytes>=b)state.tx_bytes+=b;}
  else {increment(&state.rx_transfers);if(!error && UINT32_MAX-state.rx_bytes>=b)state.rx_bytes+=b;}
 }else if(stage==6)state.interrupt_status=a;
 else if(stage==7)state.version_rpc_error=error;
 else if(stage==8){state.tlv_length=a;state.endpoint_length=b;state.endpoint_kind=c;}
 else if(stage==9){if(error)increment(&state.rpc_decode_errors);else{state.rpc_type=a;state.rpc_id=b;state.rpc_uid=c;state.rpc_payload=d;}}
 else if(stage==10){state.request_id=a;state.request_payload=b;state.request_uid=c;state.request_checksum=(a==350||a==257)?d:0;}
 else if(stage==11){if(state.tag_count<8){state.tags[state.tag_count][0]=a;state.tags[state.tag_count][1]=b;state.tags[state.tag_count][2]=c;}increment(&state.tag_count);}
 if(error && stage!=7 && stage!=9){increment(&state.bus_errors);state.last_bus_error=error;}
 k_spin_unlock(&trace_lock,key);
}
void p4_c6_trace_json(int index,char *out,size_t n)
{
 if(index==-4){
#if defined(CONFIG_P4_HOSTED)
  snprintf(out,n,"{\"available\":false,\"reason\":\"read-only probe disabled in hosted profile\"}");return;
#else
  k_spinlock_key_t key=k_spin_lock(&trace_lock);bool busy=control.busy;int result=control.result,reply=control.reply_id,status=control.reply_status;int64_t elapsed=control.elapsed;unsigned count=control.count;k_spin_unlock(&trace_lock,key);
  snprintf(out,n,"{\"busy\":%s,\"read_only_query_count\":%u,\"result\":%d,\"reply_id\":%d,\"reply_status\":%d,\"elapsed_ms\":%lld,\"address_recorded\":false,\"rf_configuration_requests\":false}",busy?"true":"false",count,result,reply,status,(long long)elapsed);return;
#endif
 }
 trace_state copy;k_spinlock_key_t key=k_spin_lock(&trace_lock);copy=state;k_spin_unlock(&trace_lock,key);
 if(index>=0 && index<8 && (uint32_t)index<copy.valid_headers){
  trace_header *h=&copy.first[index];
  snprintf(out,n,"{\"if\":%u,\"number\":%u,\"flags\":%u,\"packet_type\":%u,\"length\":%u,\"offset\":%u,\"sequence\":%u}",h->interface,h->number,h->flags,h->packet_type,h->length,h->offset,h->sequence);
 }else if(index==-1){
  snprintf(out,n,"{\"enabled\":true,\"rx_polls\":%u,\"rx_counter\":%u,\"rx_consumed\":%u,\"tx_credit_polls\":%u,\"tx_credits\":%u,\"tx_spent\":%u,\"rx_transfers\":%u,\"rx_bytes\":%u,\"tx_transfers\":%u,\"tx_bytes\":%u,\"valid_headers\":%u,\"invalid_headers\":%u,\"bus_errors\":%u,\"last_bus_error\":%d,\"floating_reads\":%u,\"interrupt_status\":%u,\"version_rpc_error\":%d}",
   copy.rx_polls,copy.rx_counter,copy.rx_consumed,copy.tx_credit_polls,copy.tx_credits,copy.tx_spent,copy.rx_transfers,copy.rx_bytes,copy.tx_transfers,copy.tx_bytes,copy.valid_headers,copy.invalid_headers,copy.bus_errors,copy.last_bus_error,copy.floating_reads,copy.interrupt_status,copy.version_rpc_error);
 }else if(index==-2){
  snprintf(out,n,"{\"tlv_length\":%u,\"endpoint_length\":%u,\"endpoint_kind\":%u,\"rpc_type\":%u,\"rpc_id\":%u,\"rpc_uid\":%u,\"rpc_payload\":%u,\"rpc_decode_errors\":%u,\"tag_count\":%u}",copy.tlv_length,copy.endpoint_length,copy.endpoint_kind,copy.rpc_type,copy.rpc_id,copy.rpc_uid,copy.rpc_payload,copy.rpc_decode_errors,copy.tag_count);
 }else if(index==-3)snprintf(out,n,"{\"request_id\":%u,\"request_payload\":%u,\"request_uid\":%u,\"request_checksum\":%u}",copy.request_id,copy.request_payload,copy.request_uid,copy.request_checksum);
 else if(index>=8 && index<16 && (uint32_t)(index-8)<copy.tag_count)snprintf(out,n,"{\"tag\":%u,\"length\":%u,\"capability_value\":%u}",copy.tags[index-8][0],copy.tags[index-8][1],copy.tags[index-8][2]);
 else snprintf(out,n,"{\"present\":false}");
}
#else
void p4_c6_trace_json(int index,char *out,size_t n){(void)index;snprintf(out,n,"{\"enabled\":false}");}
int p4_c6_query_start(void){return 0;}
unsigned p4_c6_query_count(void){return 0;}
#endif
```

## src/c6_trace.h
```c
/* SPDX-License-Identifier: MPL-2.0 */
#pragma once
#include <stddef.h>
void p4_c6_trace_json(int index,char *out,size_t capacity);
int p4_c6_query_start(void);
unsigned p4_c6_query_count(void);
```

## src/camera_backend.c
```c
/* SPDX-License-Identifier: MIT */
#include <zephyr/kernel.h>
#include <zephyr/cache.h>
#include <zephyr/multi_heap/shared_multi_heap.h>
#include <zephyr/sys/atomic.h>
#include <errno.h>
#include <stdio.h>
#include <string.h>
#include "camera_backend.h"
#include "p4_video.h"
#include "discovery_backend.h"
void *image_alloc(size_t n){return shared_multi_heap_aligned_alloc(SMH_REG_ATTR_EXTERNAL,64,n);}
void image_free(void *p){if(p)shared_multi_heap_free(p);}
K_SEM_DEFINE(requested,0,1);
K_MUTEX_DEFINE(state_mutex);
static atomic_t cancelled;
enum { IDLE, CAPTURING, READY, ERROR, QUARANTINED };
static int state;
static int owner;
static uint64_t ready_time;
static image_view frame;
static const char *capture_stage="idle"; /* worker only; copied at completion */
static char message[192]="native Zephyr: idle; sensor/CSI capture available for test";
bool p4_capture_cancelled(void){return atomic_get(&cancelled)!=0;}
int camera_available(void){return device_is_ready(p4_csi_device());}

/* Runs on the dedicated Zephyr camera thread. Contains no SmallVM objects.
 * Store adoption is deferred to camera_result() on the VM thread. */
int p4_video_capture(image_view *out)
{
    capture_stage="format";
    const struct device *dev=p4_csi_device();
    if(!device_is_ready(dev))return -ENODEV;
    struct video_format fmt={.type=VIDEO_BUF_TYPE_OUTPUT};
    int error=video_get_format(dev,&fmt);
    if(error)return error;
    if(fmt.width>IMAGE_MAX_WIDTH || fmt.height>IMAGE_MAX_HEIGHT ||
       fmt.pixelformat!=VIDEO_PIX_FMT_RGB565 || fmt.size!=fmt.width*fmt.height*2 ||
       (fmt.size&63))return -EINVAL;
    uint8_t *pixels=image_alloc(fmt.size+64);if(!pixels)return -ENOMEM;
    memset(pixels,0,fmt.size);memset(pixels+fmt.size,0xa5,64);
    /* Flush the guard too: invalidating a dirty, never-flushed guard would
     * discard our marker and falsely report DMA overflow. */
    error=sys_cache_data_flush_range(pixels,fmt.size+64);
    /* Public video_enqueue resolves by registered pool index. Import external
     * storage instead of passing an unregistered stack video_buffer. */
    struct video_buffer *b=video_import_buffer(pixels,fmt.size);
    if(!b){image_free(pixels);return -ENOMEM;}
    b->type=VIDEO_BUF_TYPE_OUTPUT;
    struct video_buffer *done=NULL;
    if(!error)error=video_set_format(dev,&fmt);
    if(!error){capture_stage="enqueue";error=video_enqueue(dev,b);}
    if(!error){capture_stage="start";error=video_stream_start(dev,VIDEO_BUF_TYPE_OUTPUT);}
    if(!error){capture_stage="frame";error=video_dequeue(dev,&done,K_SECONDS(3));}
    int stopped=video_stream_stop(dev,VIDEO_BUF_TYPE_OUTPUT);
    if(stopped==-EBUSY){
        /* Never free memory that an unquiesced DMA might still write. */
        *out=(image_view){fmt.width,fmt.height,fmt.pitch,IMAGE_RGB565,fmt.size,pixels};
        return -EBUSY;
    }
    video_driver_flush(dev,true);
    if(!error)error=stopped;
    if(!error && (done!=b || b->bytesused!=fmt.size))error=-EIO;
    video_buffer_release(b); /* external storage remains owned by us */
    int cache_error=sys_cache_data_invd_range(pixels,fmt.size+64);
    if(!error)error=cache_error;
    for(unsigned i=0;i<64;i++)if(pixels[fmt.size+i]!=0xa5){capture_stage="guard";error=-EOVERFLOW;}
    if(!error && p4_capture_cancelled())error=-ECANCELED;
    if(error){image_free(pixels);return error;}
    *out=(image_view){fmt.width,fmt.height,fmt.pitch,IMAGE_RGB565,fmt.size,pixels};
    return 0;
}
static void worker(void *a,void *b,void *c)
{
    ARG_UNUSED(a);ARG_UNUSED(b);ARG_UNUSED(c);
    for(;;){
        k_sem_take(&requested,K_FOREVER);
        image_view result={0};int error=p4_video_capture(&result);
        k_mutex_lock(&state_mutex,K_FOREVER);
        if(error==-EBUSY && result.pixels){frame=result;state=QUARANTINED;
            snprintf(message,sizeof(message),"DMA shutdown failed; buffer retained; reset required");}
        else if(p4_capture_cancelled()){
            if(result.pixels)image_free(result.pixels);
            state=IDLE;
            snprintf(message,sizeof(message),"native Zephyr: cancelled; sensor stopped");
        }else if(error){state=ERROR;
            snprintf(message,sizeof(message),"capture error %d at %s; %s; sensor stopped",error,capture_stage,p4_video_diagnostic());}
        else{frame=result;state=READY;ready_time=k_uptime_get();
            snprintf(message,sizeof(message),"native Zephyr: %ux%u RGB565 ready; sensor stopped",result.width,result.height);}
        k_mutex_unlock(&state_mutex);
    }
}
K_THREAD_DEFINE(camera_thread,8192,worker,NULL,NULL,NULL,6,0,0);
int camera_request_owned(int requested_owner)
{
    if(requested_owner!=CAMERA_OWNER_VM&&requested_owner!=CAMERA_OWNER_POSE&&requested_owner!=CAMERA_OWNER_TUNER)return 0;
    if(p4_discovery_busy())return 0;
    k_mutex_lock(&state_mutex,K_FOREVER);
    if(state==CAPTURING || state==READY || state==QUARANTINED){k_mutex_unlock(&state_mutex);return 0;}
    if(!device_is_ready(p4_csi_device()) || image_count()==IMAGE_SLOTS ||
       image_bytes_used()+IMAGE_MAX_WIDTH*IMAGE_MAX_HEIGHT*2>IMAGE_BUDGET){
        snprintf(message,sizeof(message),"camera unavailable or image capacity exhausted");
        k_mutex_unlock(&state_mutex);return 0;
    }
    atomic_clear(&cancelled);state=CAPTURING;owner=requested_owner;ready_time=0;
    snprintf(message,sizeof(message),"native Zephyr: capturing");
    k_sem_give(&requested);k_mutex_unlock(&state_mutex);return 1;
}
int camera_request(void){return camera_request_owned(CAMERA_OWNER_VM);}
int camera_busy(void)
{ k_mutex_lock(&state_mutex,K_FOREVER);int busy=state==CAPTURING;k_mutex_unlock(&state_mutex);return busy; }
int camera_result_owned(int requested_owner)
{
    k_mutex_lock(&state_mutex,K_FOREVER);int handle=0;
    if(owner!=requested_owner){k_mutex_unlock(&state_mutex);return 0;}
    if(state==READY){handle=image_adopt(frame.width,frame.height,frame.format,frame.pixels,frame.bytes);
        if(!handle){image_free(frame.pixels);snprintf(message,sizeof(message),"image capacity exhausted; capture released");}
        memset(&frame,0,sizeof(frame));state=IDLE;}
    else if(state==ERROR)state=IDLE;
    k_mutex_unlock(&state_mutex);return handle;
}
int camera_result(void){return camera_result_owned(CAMERA_OWNER_VM);}
uint64_t camera_ready_time_owned(int requested_owner){
    k_mutex_lock(&state_mutex,K_FOREVER);uint64_t time=owner==requested_owner?ready_time:0;k_mutex_unlock(&state_mutex);return time;
}
static void discard(int requested_owner)
{
    k_mutex_lock(&state_mutex,K_FOREVER);
    if(requested_owner>=0&&owner!=requested_owner){k_mutex_unlock(&state_mutex);return;}
    atomic_set(&cancelled,1);
    if(state==READY){image_free(frame.pixels);memset(&frame,0,sizeof(frame));state=IDLE;}
    if(state==ERROR)state=IDLE;
    k_mutex_unlock(&state_mutex);
}
void camera_discard(void){discard(-1);}
void camera_discard_owned(int requested_owner){discard(requested_owner);}
const char *camera_status(void)
{
    static char snapshot[sizeof(message)];
    k_mutex_lock(&state_mutex,K_FOREVER);memcpy(snapshot,message,sizeof(message));k_mutex_unlock(&state_mutex);
    return snapshot;
}
```

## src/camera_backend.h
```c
/* SPDX-License-Identifier: MIT */
#pragma once
#include "image_store.h"
int camera_request(void);
int camera_available(void);
int camera_busy(void);
int camera_result(void);
enum { CAMERA_OWNER_VM=0,CAMERA_OWNER_POSE=1,CAMERA_OWNER_TUNER=2 };
int camera_request_owned(int owner);
int camera_result_owned(int owner);
void camera_discard_owned(int owner);
uint64_t camera_ready_time_owned(int owner);
void camera_discard(void);
const char *camera_status(void);
int p4_sensor_ids(unsigned *imx,unsigned *ov);
int p4_video_capture(image_view *out);
```

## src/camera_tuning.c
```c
/* SPDX-License-Identifier: MPL-2.0 */
/* VM-thread service; settings are protected by the native sensor's mutex. */
#include "camera_tuning.h"
#include "camera_backend.h"
#include "p4_video.h"
#include "serial_speed.h"
#include "vm/interp.h"
#include <zephyr/kernel.h>
#include <errno.h>
#include <stdio.h>
#include <string.h>
enum {IDLE,CAPTURING,READY,ERROR};
static unsigned state;
static uint32_t session;
static int image,last_error;
static int64_t deadline;
static p4_camera_settings used;
static unsigned frame_width=320,frame_height=180,capture_ms;
static int64_t capture_began;
static unsigned u16(const uint8_t *p){return p[0]|(unsigned)p[1]<<8;}
static uint32_t u32(const uint8_t *p){return u16(p)|(uint32_t)u16(p+2)<<16;}
static void put32(uint8_t *p,uint32_t v){for(unsigned i=0;i<4;i++)p[i]=v>>(8*i);}
int p4_camera_tuning_settings(int exposure,int analog,int digital){
    if(camera_busy())return -EBUSY;
    if(exposure<0||analog<0||digital<0)return -EINVAL;
    p4_camera_settings s={(unsigned)exposure,(unsigned)analog,(unsigned)digital};return p4_sensor_settings_set(&s);
}
void p4_camera_tuning_status(char *out,size_t n){
    p4_camera_settings s;bool supported=p4_sensor_settings(&s);
    snprintf(out,n,"{\"supported\":%s,\"exposure\":%u,\"analog\":%u,\"digital\":%u,\"pattern\":%u,\"state\":%u,\"handle\":%d,\"used_exposure\":%u,\"used_analog\":%u,\"used_digital\":%u,\"error\":%d,\"width\":%u,\"height\":%u,\"capture_ms\":%u,\"baud\":%u}",
        supported?"true":"false",s.exposure,s.analog,s.digital,CONFIG_P4_IMX219_TEST_PATTERN,state,image,used.exposure,used.analog,used.digital,last_error,frame_width,frame_height,capture_ms,p4_serial_speed_baud());
}
void p4_camera_tuning_reset(void){
    if(state==CAPTURING)camera_discard_owned(CAMERA_OWNER_TUNER);
    if(image)image_release(image);
    image=0;session=0;state=IDLE;last_error=0;
}
void p4_camera_tuning_poll(void){
    if(!session)return;
    if(k_uptime_get()>=deadline){p4_camera_tuning_reset();return;}
    if(state!=CAPTURING||camera_busy())return;
    int original=camera_result_owned(CAMERA_OWNER_TUNER);
    if(original){image=image_resize(original,frame_width,frame_height,IMAGE_RGB565);image_release(original);}
    if(!image){state=ERROR;last_error=-EIO;deadline=k_uptime_get()+3000;return;}
    capture_ms=(unsigned)(k_uptime_get()-capture_began);
    /* Baseline UART wire time plus bounded per-chunk/browser overhead. */
    uint64_t bytes=(uint64_t)frame_width*frame_height*2;
    uint64_t lease=10000+bytes*10000/115200+((bytes+511)/512)*12;
    if(lease>300000)lease=300000;
    state=READY;deadline=k_uptime_get()+lease;
}
static void reply(unsigned op,uint32_t request,uint32_t client,int status){
    uint8_t out[352]={0};memcpy(out,"P4CC",4);out[4]=1;out[5]=op;out[6]=status;out[7]=state;put32(out+8,request);put32(out+12,client);
    p4_camera_tuning_status((char *)out+16,sizeof(out)-16);
    waitAndSendMessage(213,0,16+strlen((char *)out+16),(char *)out);
}
void p4_camera_tuning_open(void){if(hasOutputSpace(357))reply(128,0,0,0);}
void p4_camera_tuning_message(int type,int n,const char *body){
    const uint8_t *p=(const uint8_t *)body;
    if(type!=213||n!=24||memcmp(p,"P4CC",4)||p[4]!=1||p[5]>5||u16(p+6)||u16(p+22)||!hasOutputSpace(357))return;
    unsigned op=p[5],exposure=u16(p+16),analog=u16(p+18),digital=u16(p+20);uint32_t request=u32(p+8),client=u32(p+12);int status=0;
    if((op!=1&&op!=3&&(exposure||analog||digital))||((op<=2)&&client)||((op>=3)&&(!client||client>0x1fffffffu))){reply(op,request,client,1);return;}
    if(op==3&&(digital||((exposure||analog)&&(exposure<16||exposure>1280||analog<16||analog>720)))){reply(op,request,client,1);return;}
    p4_camera_tuning_poll();
    if(op==1){int e=p4_camera_tuning_settings(exposure,analog,digital);status=e==-EBUSY?3:(e==-ENOTSUP?2:(e?1:0));}
    else if(op==2){if(camera_busy())status=3;else{p4_camera_settings s;if(!p4_sensor_settings(&s))status=2;else p4_sensor_settings_reset();}}
    else if(op==3){
        if(session||!p4_sensor_settings(&used)||!camera_request_owned(CAMERA_OWNER_TUNER))status=3;
        else{frame_width=exposure?exposure:320;frame_height=analog?analog:180;capture_ms=0;capture_began=k_uptime_get();session=client;state=CAPTURING;last_error=0;deadline=k_uptime_get()+8000;}
    }else if(op>=4){if(client!=session)status=1;else if(op==5)p4_camera_tuning_reset();}
    reply(op,request,client,status);
}
```

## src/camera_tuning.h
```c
/* SPDX-License-Identifier: MIT */
#pragma once
#include <stddef.h>
void p4_camera_tuning_message(int type,int bytes,const char *body);
void p4_camera_tuning_poll(void);
void p4_camera_tuning_reset(void);
int p4_camera_tuning_settings(int exposure,int analog,int digital);
void p4_camera_tuning_status(char *out,size_t n);
void p4_camera_tuning_open(void);
```

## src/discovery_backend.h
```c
/* SPDX-License-Identifier: MIT */
#pragma once
#include <stddef.h>
#include <stdbool.h>
#include "discovery.h"
void p4_discovery_init(void);
bool p4_discovery_busy(void);
bool p4_discovery_scan(int bus,bool identify);
void p4_discovery_cancel(void);
unsigned p4_discovery_count(void);
void p4_discovery_ref(int index,char *,size_t);
bool p4_discovery_device(const char *,discovery_device *);
bool p4_discovery_read(const char *,const char *);
discovery_reading p4_discovery_reading(void);
void p4_discovery_status(char *,size_t);
void p4_discovery_read_text(char *,size_t);
```
